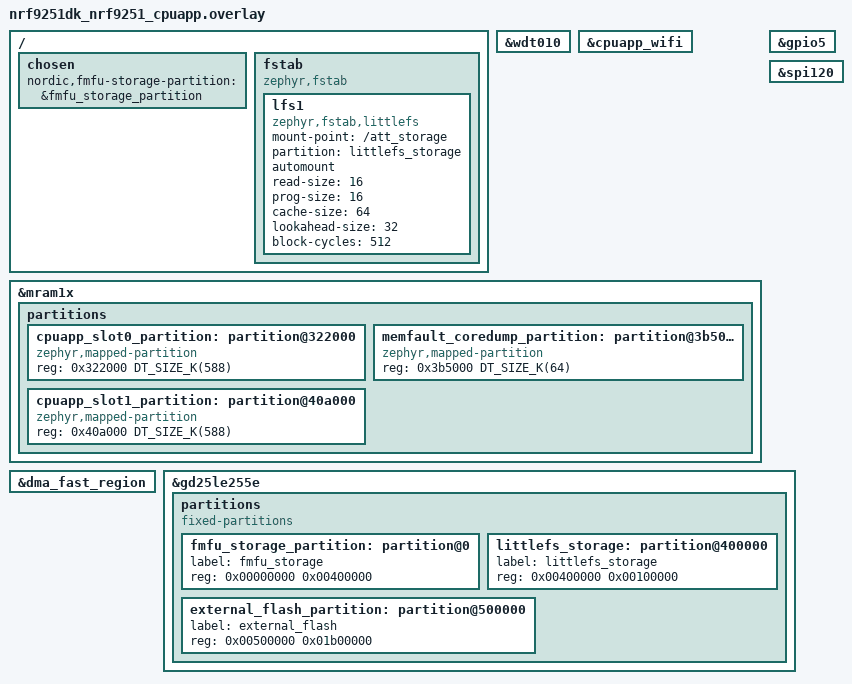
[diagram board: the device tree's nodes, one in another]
/*
 * Copyright (c) 2026 Nordic Semiconductor ASA
 *
 * SPDX-License-Identifier: LicenseRef-Nordic-5-Clause
 */

/* Used for hardware fallback by task watchdog. */
&wdt010 {
	status = "okay";
};

/* Built-in Wi-Fi, used for Wi-Fi location. */
&cpuapp_wifi {
	status = "okay";
};

/* Carve the Memfault coredump partition out of the application slots. Must match
 * app/sysbuild/mcuboot/boards/nrf9251dk_nrf9251_cpuapp.overlay.
 */
&mram1x {
	partitions {
		cpuapp_slot0_partition: partition@322000 {
			compatible = "zephyr,mapped-partition";
			reg = <0x322000 DT_SIZE_K(588)>;
		};

		memfault_coredump_partition: partition@3b5000 {
			compatible = "zephyr,mapped-partition";
			reg = <0x3b5000 DT_SIZE_K(64)>;
		};

		cpuapp_slot1_partition: partition@40a000 {
			compatible = "zephyr,mapped-partition";
			reg = <0x40a000 DT_SIZE_K(588)>;
		};
	};
};

&dma_fast_region {
	status = "okay";
};

&gpio5 {
	status = "okay";
};

&spi120 {
	status = "okay";
};

/* External flash (32 MiB). fmfu_storage_partition is reserved for full modem FOTA. */
flash_ext: &gd25le255e {
	status = "okay";

	partitions {
		compatible = "fixed-partitions";
		#address-cells = <1>;
		#size-cells = <1>;

		fmfu_storage_partition: partition@0 {
			label = "fmfu_storage";
			reg = <0x00000000 0x00400000>;
		};

		littlefs_storage: partition@400000 {
			label = "littlefs_storage";
			reg = <0x00400000 0x00100000>;
		};

		external_flash_partition: partition@500000 {
			label = "external_flash";
			reg = <0x00500000 0x01b00000>;
		};
	};
};

/ {
	chosen {
		nordic,fmfu-storage-partition = &fmfu_storage_partition;
	};

	fstab {
		compatible = "zephyr,fstab";
		lfs1: lfs1 {
			compatible = "zephyr,fstab,littlefs";
			mount-point = "/att_storage";
			partition = <&littlefs_storage>;
			automount;
			read-size = <16>;
			prog-size = <16>;
			cache-size = <64>;
			lookahead-size = <32>;
			block-cycles = <512>;
		};
	};
};
